# f28p65x_cpu1_lfu_regs register map
Vendor: Texas Instruments
Peripheral module from a debugger description file (folder C2000).
Address unit: 16 bits
Registers are 32-bit, read-write, no defined reset value unless marked. A register's access mark holds for its fields unless they carry their own. Offsets are as the file gives them; lines under a group give offsets from that group; [hi:lo] are bit positions; {n}, {i} and the like mark numbered series; 'fields as' and 'values as' point back to an identical list; <NAME> marks a mode.

## CPU1_LFU_REGS — CPU1 LFU Registers
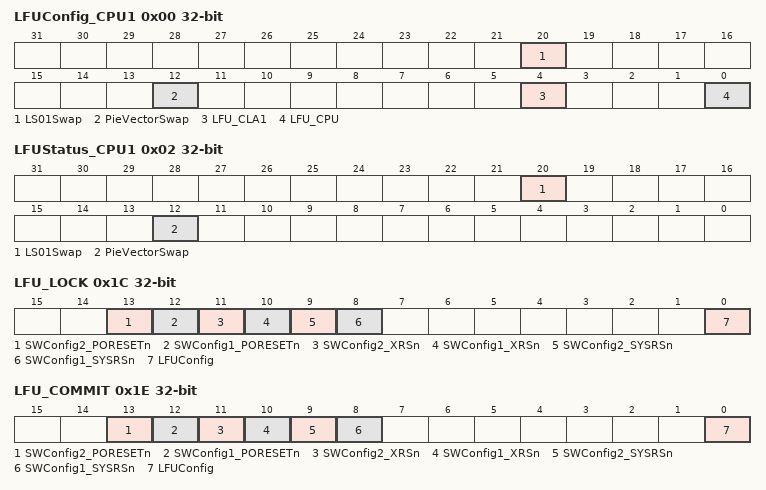
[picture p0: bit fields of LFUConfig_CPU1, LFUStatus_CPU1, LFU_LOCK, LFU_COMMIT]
0x00 LFUConfig_CPU1 — LFU configuration Register
  [20] LS01Swap — Swap LS0 and LS1 memory
  [12] PieVectorSwap — Swap of pie vector table
  [4] LFU_CLA1 — SW configuration to implement LFU
  [0] LFU_CPU — SW configuration to implement LFU
0x02 LFUStatus_CPU1 ro — LFU Configuration Status Register
  [20] LS01Swap — Indicate the status of LS0/LS1 memory swap
  [12] PieVectorSwap — Indicate the status of PieVectorSwap
0x10 SWConfig1_SYSRSn — Spare registers reset by SYSRSn
  [31:0] BITS — SW configurable bits
0x12 SWConfig2_SYSRSn — Spare registers reset by SYSRSn
  [31:0] BITS — SW configurable bits
0x14 SWConfig1_XRSn — Spare registers reset by XRSn
  [31:0] BITS — SW configurable bits
0x16 SWConfig2_XRSn — Spare registers reset by XRSn
  [31:0] BITS — SW configurable bits
0x18 SWConfig1_PORESETn — Spare registers reset by PORESETn
  [31:0] BITS — SW configurable bits
0x1A SWConfig2_PORESETn — Spare registers reset by PORESETn
  [31:0] BITS — SW configurable bits
0x1C LFU_LOCK — LFU Lock Configuration
  [13] SWConfig2_PORESETn — Register lock configuration
  [12] SWConfig1_PORESETn — Register lock configuration
  [11] SWConfig2_XRSn — Register lock configuration
  [10] SWConfig1_XRSn — Register lock configuration
  [9] SWConfig2_SYSRSn — Register lock configuration
  [8] SWConfig1_SYSRSn — Register lock configuration
  [0] LFUConfig — Register lock configuration
0x1E LFU_COMMIT — LFU Commit Configuration
  [13] SWConfig2_PORESETn — Register commit configuration
  [12] SWConfig1_PORESETn — Register commit configuration
  [11] SWConfig2_XRSn — Register commit configuration
  [10] SWConfig1_XRSn — Register commit configuration
  [9] SWConfig2_SYSRSn — Register commit configuration
  [8] SWConfig1_SYSRSn — Register commit configuration
  [0] LFUConfig — Register commit configuration
